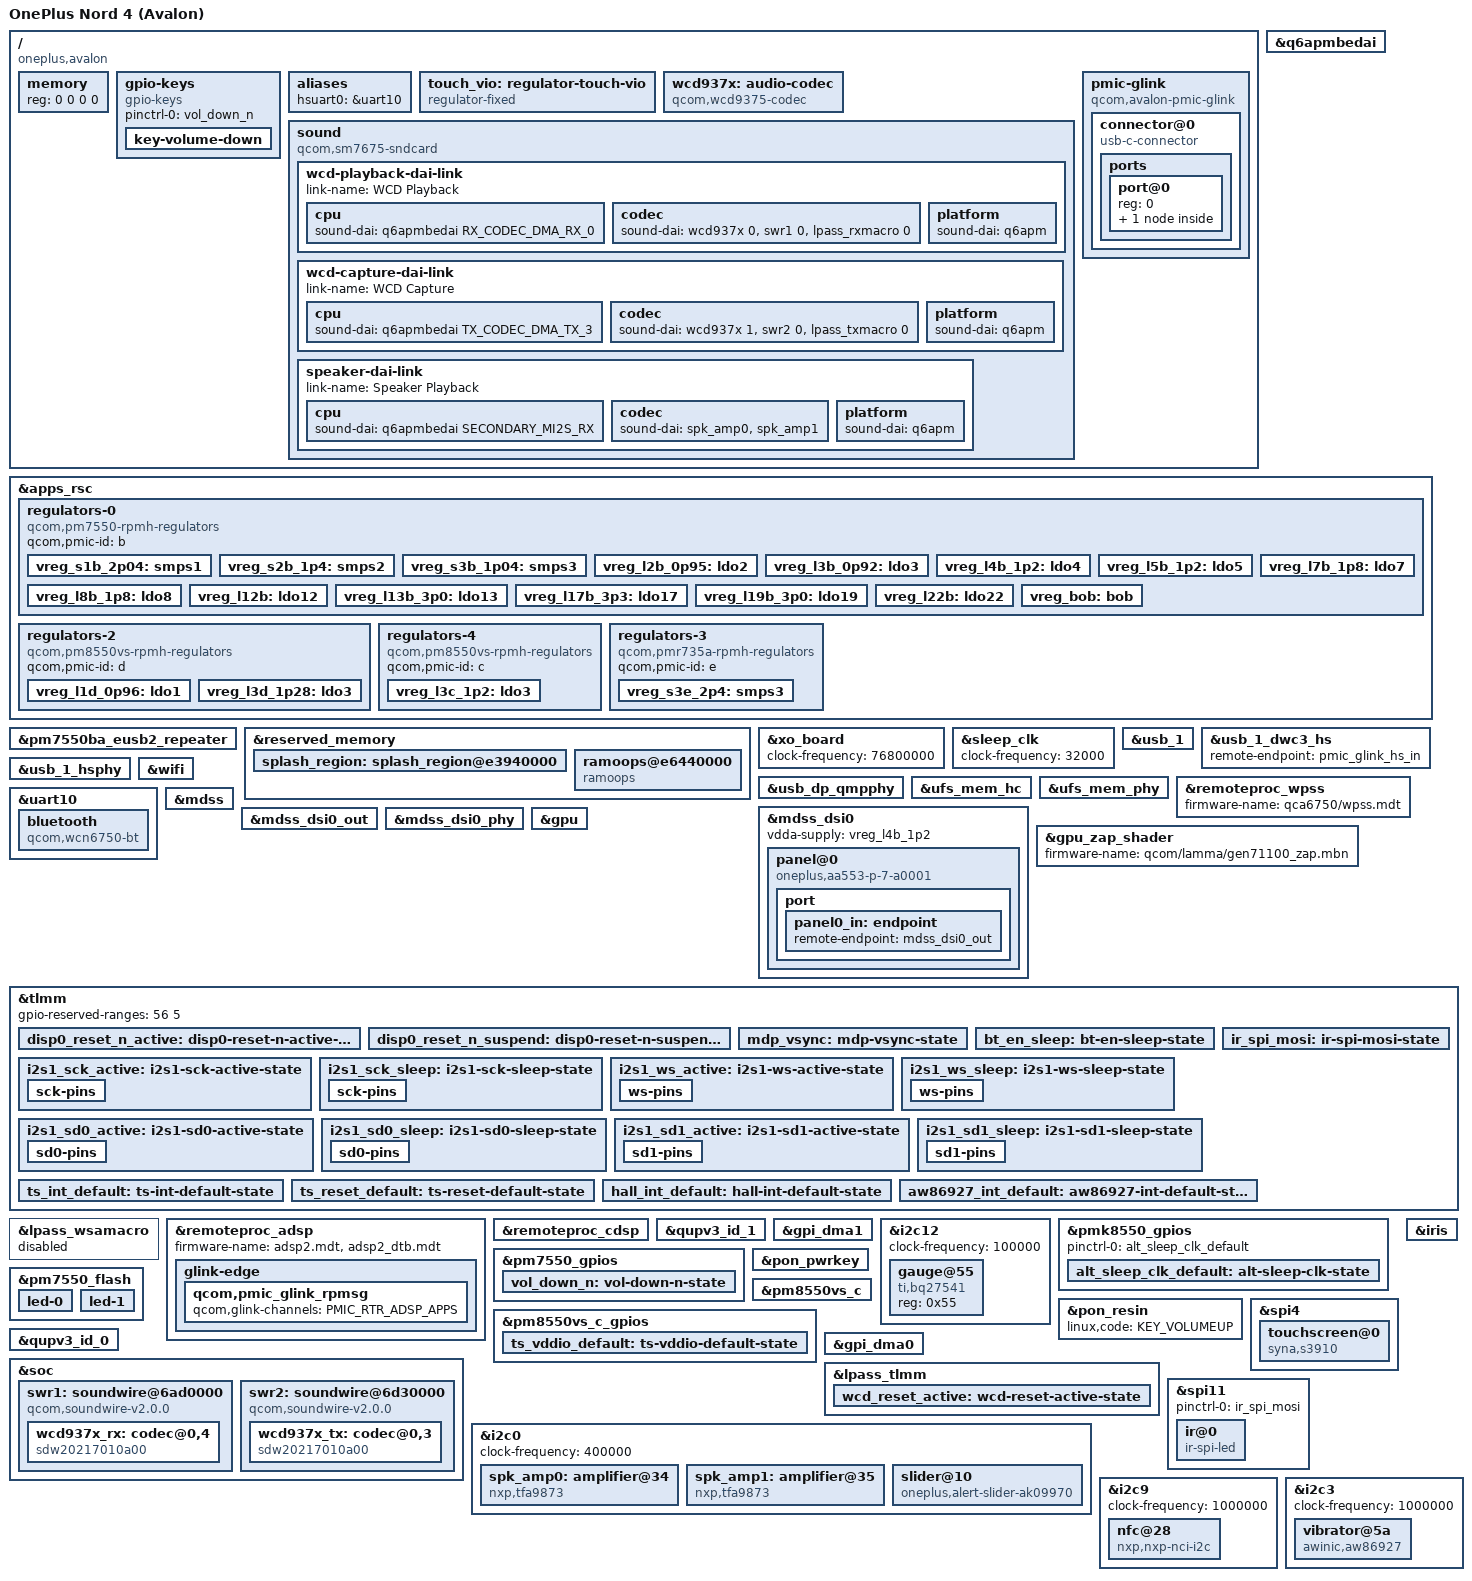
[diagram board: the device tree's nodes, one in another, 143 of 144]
// SPDX-License-Identifier: BSD-3-Clause
/*
 * OnePlus Nord 4 (Avalon), SM7675 / Lamma.
 *
 * Scope: the display subsystem and its AA553-P-7-A0001 panel, the iris video
 * decoder, the SN220U NFC controller, the AW86927 haptics motor, ramoops, the
 * USB controller with its Type-C role switch (device by default), the
 * ADSP/PMIC GLINK battery path, the WCN6750 Wi-Fi and Bluetooth path over the
 * WPSS remoteproc, the Adreno 732 GPU, the audio card and the power and
 * volume keys. SD stays disabled. The battery readout, the Wi-Fi interface,
 * the GPU probe, the panel, touch, the haptics motor, a decode and the NFC
 * controller's own answering have been exercised on hardware; the
 * charge-ceiling write, a Wi-Fi scan and the USB host role have not.
 *
 * Electrical values are from the downstream OnePlus device tree
 * (android_kernel_modules_and_devicetree_oneplus_sm7675, branch
 * oneplus/sm7675_b_16.0.0_nord_4, commit 150f7f8f3354dc680da90e83788bd25d9b983739),
 * not from the QRD reference board.
 */

/dts-v1/;

#include <dt-bindings/gpio/gpio.h>
#include <dt-bindings/input/linux-event-codes.h>
#include <dt-bindings/interrupt-controller/irq.h>
#include <dt-bindings/leds/common.h>
#include <dt-bindings/regulator/qcom,rpmh-regulator.h>
#include <dt-bindings/sound/qcom,q6dsp-lpass-ports.h>
#include "lamma.dtsi"
#include "pm7550.dtsi" /* PMXR2230 */
#include "pm7550ba.dtsi"
#include "pmr735a.dtsi"
#include "pmk8550.dtsi"
#include "pm8550vs.dtsi"

/ {
	model = "OnePlus Nord 4 (Avalon)";
	compatible = "oneplus,avalon", "qcom,lamma";
	chassis-type = "handset";

	/*
	 * Bootloader selection properties, copied from the shipped Avalon
	 * dtbo entry: qcom,msm-id 632 (0x278) for Lamma/Cliffs 7, board-id 8,
	 * and the pmic-id of eight 32-bit cells ending in 0x4c. ABL reads
	 * pmic-id-size as the number of u32 cells per entry and skips the
	 * PMIC match when the property length is not a multiple of it.
	 */
	qcom,msm-id = <0x278 0x10000>;
	qcom,board-id = <0x08 0x00>;
	qcom,pmic-id-size = <8>;
	qcom,pmic-id = <0x00 0x00 0x00 0x00 0x00 0x00 0x00 0x4c>;

	/*
	 * Lamma dtsi ships a placeholder memory@a0000000; this bootloader
	 * looks up the node named exactly "memory" and rewrites its reg with
	 * the DDR map, so the placeholder is dropped rather than left dead.
	 */
	/delete-node/ memory@a0000000;

	/* The bootloader rewrites reg with the real DDR size. */
	memory {
		device_type = "memory";
		reg = <0 0 0 0>;
	};

	/*
	 * The volume-down key is a board line: PMXR2230 GPIO6, driven low when
	 * pressed, with a 32 ms debounce. The downstream OnePlus board file
	 * deletes the reference board's key node and restates it this way
	 * (vendor/qcom/proprietary/devicetree/oplus/tp/avalon-oplus-tp-24211.dtsi:476-493),
	 * which also swaps the key code the reference board uses for this pin
	 * (KEY_VOLUMEUP in qcom/cliffs-mtp.dtsi:72-86) for KEY_VOLUMEDOWN.
	 * Volume-up and power are PMK8550 PON inputs instead; see below.
	 */
	gpio-keys {
		compatible = "gpio-keys";

		pinctrl-0 = <&vol_down_n>;
		pinctrl-names = "default";

		key-volume-down {
			label = "Volume Down";
			gpios = <&pm7550_gpios 6 GPIO_ACTIVE_LOW>;
			linux,code = <KEY_VOLUMEDOWN>;
			debounce-interval = <32>;
			linux,can-disable;
			wakeup-source;
		};
	};

	aliases {
		/*
		 * The Bluetooth UART, uart10, is neither the console nor a
		 * serial port, so it gets no "serial" alias. qcom_geni_serial
		 * asks for "serial" first and falls back to "hsuart" when the
		 * node has none (drivers/tty/serial/qcom_geni_serial.c:1821-1823);
		 * without either the probe is rejected before the port exists
		 * ("Invalid line -19"), so no tty and no serdev either.
		 * Downstream aliases the same instance the same way:
		 * hsuart0 = &qupv3_se10_4uart (cliffs.dtsi:48-53).
		 */
		hsuart0 = &uart10;
	};

	/*
	 * The S3910's 1.8 V I/O rail. The downstream Avalon node has no
	 * vcc_1v8-supply; instead it names synaptics,avdd-gpio =
	 * <&pm8550vs_c_gpios 3 0x1>, pinctrl state ts_vddio_active_primary
	 * (power-source 1 = 1.8 V), and the SPI platform driver drives that
	 * pad to synaptics,power-on-state = 1 before it enables the analog
	 * rail (android_kernel_modules_and_devicetree_oneplus_sm7675,
	 * oneplus/sm7675_b_16.0.0_nord_4, 150f7f8f3354,
	 * vendor/oplus/kernel/touchpanel/synaptics_hbp/syna_tcm2_platform_spi.c:
	 * 366-402,464-490). Model it as the switched rail it is.
	 */
	touch_vio: regulator-touch-vio {
		compatible = "regulator-fixed";
		regulator-name = "touch_vio";
		regulator-min-microvolt = <1800000>;
		regulator-max-microvolt = <1800000>;
		enable-active-high;
		gpios = <&pm8550vs_c_gpios 3 GPIO_ACTIVE_HIGH>;
	};

	/*
	 * The WCD937x codec, split into the RX and TX SoundWire slaves below.
	 * Supplies: L7B at 1.8 V feeds vdd-rxtx, vdd-px and vdd-buck (13890,
	 * 13890 and 361110 uA; rxtx and vddpx static, buck on demand) and BOB
	 * at 3.296 V feeds vdd-mic-bias at 6760 uA
	 * (audio-devicetree/cliffs-audio-overlay.dtsi:318-332 and
	 * oplus/cliffs-audio-overlay-common.dtsi:33-39). Downstream's final
	 * Avalon overlay leaves the three mic biases at 1800 mV
	 * (oplus/avalon-24211-audio-cliffs-overlay.dtsi:44-54 sets the MBHC
	 * thresholds, not the bias voltages; the bias values in
	 * cliffs-audio-overlay.dtsi:330-332 are 1800 mV). The reset line is
	 * LPASS LPI GPIO12 (see the state below).
	 *
	 * The variant is not recorded anywhere downstream: the driver accepts
	 * both ids, reads the chip id from the efuse and only prints the
	 * unknown case (sound/soc/codecs/wcd937x.c:2512-2522, :2981-2984), so
	 * the compatible pair names what the board may carry and the first
	 * boot reports which one is fitted.
	 */
	wcd937x: audio-codec {
		compatible = "qcom,wcd9375-codec", "qcom,wcd9370-codec";

		pinctrl-0 = <&wcd_reset_active>;
		pinctrl-names = "default";

		reset-gpios = <&lpass_tlmm 12 GPIO_ACTIVE_LOW>;

		vdd-buck-supply = <&vreg_l7b_1p8>;
		vdd-rxtx-supply = <&vreg_l7b_1p8>;
		vdd-px-supply = <&vreg_l7b_1p8>;
		vdd-mic-bias-supply = <&vreg_bob>;

		qcom,micbias1-microvolt = <1800000>;
		qcom,micbias2-microvolt = <1800000>;
		qcom,micbias3-microvolt = <1800000>;
		/*
		 * The board wires three mic biases (downstream enables
		 * MIC BIAS1-3 only, oplus/avalon-24211-audio-cliffs-overlay.dtsi:48-54).
		 * The binding requires the fourth value and the driver's
		 * max_bias is 3, so it never programs this one; 1.8 V is the
		 * driver's own default for an unset bias
		 * (sound/soc/codecs/wcd-common.c:36-61).
		 */
		qcom,micbias4-microvolt = <1800000>;

		qcom,rx-device = <&wcd937x_rx>;
		qcom,tx-device = <&wcd937x_tx>;

		#sound-dai-cells = <1>;
	};

	/*
	 * The one card this board can register: the AudioReach machine driver
	 * (sound/soc/qcom/sc8280xp.c, compatible added for sm7675) builds the
	 * links from this node through qcom_snd_parse_of()
	 * (sound/soc/qcom/common.c:26-172). The MI2S1 pins carry the speaker
	 * amplifiers (oplus,speaker-i2s-id = <1>,
	 * oplus/avalon-24211-audio-cliffs-overlay.dtsi:119-120) and the four
	 * active states are the ones described above; the card applies them
	 * because the q6apm DAI does not.
	 */
	sound {
		compatible = "qcom,sm7675-sndcard", "qcom,sm8450-sndcard";
		model = "OnePlus Nord 4";

		pinctrl-0 = <&i2s1_sck_active>, <&i2s1_ws_active>,
			    <&i2s1_sd0_active>, <&i2s1_sd1_active>;
		pinctrl-names = "default";

		/*
		 * The board's microphones are the WCD9370's analog ones: the
		 * bottom and top mics land on AMIC1/AMIC2 through MIC BIAS1/2
		 * (the vendor's capture backend is CODEC_DMA-LPAIF_RXTX-TX-3
		 * for both, odm/etc/resourcemanager.xml in the stock odm image),
		 * and the stock routing joins the codec's third input to MIC
		 * BIAS3 as well.  The last two routes join the codec's ADC
		 * outputs to the TX macro's SoundWire inputs: the codec's TX
		 * port mapping puts ADC1 and ADC2 on master port 2
		 * (qcom,tx-port-mapping = <2 2 3 4>, the same table the SM8550
		 * WCD9385 boards use), and master port 2 carries TX SWR_INPUT0..3
		 * (lpass-tx-macro.c's v9_2 widget set, which the SM8550 macro
		 * data selects).
		 */
		audio-routing = "AMIC1", "MIC BIAS1",
				"AMIC2", "MIC BIAS2",
				"AMIC3", "MIC BIAS3",
				"TX SWR_INPUT0", "ADC1_OUTPUT",
				"TX SWR_INPUT1", "ADC2_OUTPUT";

		wcd-playback-dai-link {
			link-name = "WCD Playback";

			cpu {
				sound-dai = <&q6apmbedai RX_CODEC_DMA_RX_0>;
			};

			codec {
				sound-dai = <&wcd937x 0>, <&swr1 0>,
					    <&lpass_rxmacro 0>;
			};

			platform {
				sound-dai = <&q6apm>;
			};
		};

		/*
		 * Capture: the WCD9370's ADCs leave the codec on the TX
		 * SoundWire slave (swr2, the TX macro's master) and reach the
		 * LPASS through the RXTX codec DMA's TX3 port.  The same link
		 * shape as qcm6490-idp.dts's wcd-capture-dai-link, whose codec
		 * is this one; the codec's first DAI is the RX, the second the
		 * TX (wcd937x.c's wcd937x_dais[]).
		 */
		wcd-capture-dai-link {
			link-name = "WCD Capture";

			cpu {
				sound-dai = <&q6apmbedai TX_CODEC_DMA_TX_3>;
			};

			codec {
				sound-dai = <&wcd937x 1>, <&swr2 0>,
					    <&lpass_txmacro 0>;
			};

			platform {
				sound-dai = <&q6apm>;
			};
		};

		/*
		 * Both amplifiers are fed from the same MI2S: downstream's
		 * oplus,speaker-i2s-id = <1> is the secondary MI2S, whose
		 * SCK/WS/SD0/SD1 are the TLMM i2s1 states above
		 * (oplus/avalon-24211-audio-cliffs-overlay.dtsi:113-148).
		 */
		speaker-dai-link {
			link-name = "Speaker Playback";

			cpu {
				sound-dai = <&q6apmbedai SECONDARY_MI2S_RX>;
			};

			codec {
				sound-dai = <&spk_amp0>, <&spk_amp1>;
			};

			platform {
				sound-dai = <&q6apm>;
			};
		};
	};
};

/*
 * The secondary MI2S bit clock is owned by the LPASS PRM, not by the DSP's
 * I2S endpoint: the DAI votes its frequency through q6prm at hw_params, as
 * the vendor's machine driver does (audio-kernel asoc/msm_common.c, the
 * CLOCK_ID_SEC_MI2S_IBIT branch of msm_common_snd_hw_params()).  Without the
 * vote the endpoint has no bit clock, so it never returns a buffer and the
 * playback hw_ptr stays 0.
 */
&q6apmbedai {
	clocks = <&q6prmcc LPASS_CLK_ID_SEC_MI2S_IBIT LPASS_CLK_ATTRIBUTE_COUPLE_NO>;
	clock-names = "sec-mi2s-ibit";
};

&apps_rsc {
	regulators-0 {
		compatible = "qcom,pm7550-rpmh-regulators";
		qcom,pmic-id = "b";

		/*
		 * S1B: WCN6750 WLAN vdd-1.8-xo and BT vddrfa1p7. 1856000-2040000 uV,
		 * init 1856000 (downstream qcom/cliffs-regulators.dtsi:344-346; the
		 * consumers are qca6750/vdd-1.8-xo at cliffs-qca6750.dtsi:84 and
		 * bt-vdd-rfa1 at cliffs-qca6750-bt.dtsi:35). Neither the ath11k nor
		 * the hci_qca probe runs before the WPSS firmware, so the rail is held
		 * on at the downstream boot voltage.
		 */
		vreg_s1b_2p04: smps1 {
			regulator-name = "vreg_s1b_2p04";
			regulator-min-microvolt = <1856000>;
			regulator-max-microvolt = <2040000>;
			regulator-initial-mode = <RPMH_REGULATOR_MODE_HPM>;
			regulator-always-on;
		};

		/*
		 * S2B: WLAN/BT vdd-1.3-rfa on the downstream board and the parent
		 * rail of UFS vccq. 1256000-1408000 uV, init 1256000
		 * (downstream qcom/cliffs-regulators.dtsi:358-364). Mainline has no
		 * consumer for the UFS parent vote, so the rail is held on.
		 */
		vreg_s2b_1p4: smps2 {
			regulator-name = "vreg_s2b_1p4";
			regulator-min-microvolt = <1256000>;
			regulator-max-microvolt = <1408000>;
			regulator-initial-mode = <RPMH_REGULATOR_MODE_HPM>;
			regulator-always-on;
		};

		/*
		 * S3B: WCN6750 WLAN vdd-cx-mx and BT vddaon, vddbtcxmx,
		 * vddrfacmn and vddrfa0p8. 968000-1040000 uV, init 984000
		 * (downstream qcom/cliffs-regulators.dtsi:377-379; the consumers are
		 * cliffs-qca6750.dtsi:82 and cliffs-qca6750-bt.dtsi:31-34). Held on
		 * for the same reason as S1B.
		 */
		vreg_s3b_1p04: smps3 {
			regulator-name = "vreg_s3b_1p04";
			regulator-min-microvolt = <968000>;
			regulator-max-microvolt = <1040000>;
			regulator-initial-mode = <RPMH_REGULATOR_MODE_HPM>;
			regulator-always-on;
		};

		/* L2B: USB HS PHY vdd. 880000-950000 uV, init 880000. */
		vreg_l2b_0p95: ldo2 {
			regulator-name = "vreg_l2b_0p95";
			regulator-min-microvolt = <880000>;
			regulator-max-microvolt = <950000>;
			regulator-initial-mode = <RPMH_REGULATOR_MODE_HPM>;
		};

		/* L3B: USB3-DP PHY vdda-pll. 880000-920000 uV. */
		vreg_l3b_0p92: ldo3 {
			regulator-name = "vreg_l3b_0p92";
			regulator-min-microvolt = <880000>;
			regulator-max-microvolt = <920000>;
			regulator-initial-mode = <RPMH_REGULATOR_MODE_HPM>;
		};

		/* L4B: USB HS PHY vdda12 and USB3-DP PHY vdda-phy. 1.2 V. */
		vreg_l4b_1p2: ldo4 {
			regulator-name = "vreg_l4b_1p2";
			regulator-min-microvolt = <1200000>;
			regulator-max-microvolt = <1200000>;
			regulator-initial-mode = <RPMH_REGULATOR_MODE_HPM>;
		};

		/*
		 * L5B: UFS vddp-ref-clk. 1.2 V, init 1200000 (downstream
		 * qcom/cliffs-regulators.dtsi:479-487). Mainline has no consumer, so
		 * the rail is held on for the UFS reset pull-up.
		 */
		vreg_l5b_1p2: ldo5 {
			regulator-name = "vreg_l5b_1p2";
			regulator-min-microvolt = <1200000>;
			regulator-max-microvolt = <1200000>;
			regulator-initial-mode = <RPMH_REGULATOR_MODE_HPM>;
			regulator-always-on;
		};

		/* L7B: eUSB2 repeater vdd18. 1.8 V. */
		vreg_l7b_1p8: ldo7 {
			regulator-name = "vreg_l7b_1p8";
			regulator-min-microvolt = <1800000>;
			regulator-max-microvolt = <1800000>;
			regulator-initial-mode = <RPMH_REGULATOR_MODE_HPM>;
		};

		/*
		 * L8B: panel vddio. 1.8 V, 220 mA proxy consumer
		 * (downstream qcom/cliffs-regulators.dtsi:520-530); the panel's
		 * supply entry asks for the same 1.8 V, enabled 2 ms before vci
		 * (vendor/qcom/proprietary/display-devicetree/oplus/
		 * audi-23803-display-cliffs-overlay.dtsi:21-29).
		 */
		vreg_l8b_1p8: ldo8 {
			regulator-name = "vreg_l8b_1p8";
			regulator-min-microvolt = <1800000>;
			regulator-max-microvolt = <1800000>;
			regulator-initial-mode = <RPMH_REGULATOR_MODE_HPM>;
		};

		/*
		 * L12B: UFS vcc. The PON sets 2.4 V or 2.96 V by UFS mode, so the
		 * downstream node has no min/max (qcom/cliffs-regulators.dtsi:602-616).
		 */
		vreg_l12b: ldo12 {
			regulator-name = "vreg_l12b";
			regulator-initial-mode = <RPMH_REGULATOR_MODE_HPM>;
		};

		/*
		 * L13B: the IR blaster's LED rail, 3.008 V. The downstream
		 * consumer_ir_core node names L13B at 3008000 uV
		 * (oplus/sensor/avalon-sensor-24211.dtsi:55-62), and the
		 * overlay removes the SD card's reference to the same rail
		 * (oplus/cliffs_overlay_common.dtsi:91-97). ir-spi-led looks
		 * its supply up as "irda_regulator" while its binding declares
		 * power-supply, so the rail is held on here rather than
		 * switched per transmission.
		 */
		vreg_l13b_3p0: ldo13 {
			regulator-name = "vreg_l13b_3p0";
			regulator-min-microvolt = <3008000>;
			regulator-max-microvolt = <3008000>;
			regulator-initial-mode = <RPMH_REGULATOR_MODE_HPM>;
			regulator-always-on;
		};

		/* L17B: eUSB2 repeater vdd3. 2700000-3300000 uV, init 3104000. */
		vreg_l17b_3p3: ldo17 {
			regulator-name = "vreg_l17b_3p3";
			regulator-min-microvolt = <2700000>;
			regulator-max-microvolt = <3300000>;
			regulator-initial-mode = <RPMH_REGULATOR_MODE_HPM>;
		};

		/*
		 * L19B: panel vci. The rail runs 2.6-3.544 V
		 * (downstream qcom/cliffs-regulators.dtsi:727-737) and the panel's
		 * supply entry fixes it at 3.0 V, enabled 15 ms before the reset
		 * sequence (vendor/qcom/proprietary/display-devicetree/oplus/
		 * audi-23803-display-cliffs-overlay.dtsi:32-43).
		 */
		vreg_l19b_3p0: ldo19 {
			regulator-name = "vreg_l19b_3p0";
			regulator-min-microvolt = <3000000>;
			regulator-max-microvolt = <3000000>;
			regulator-initial-mode = <RPMH_REGULATOR_MODE_HPM>;
		};

		/*
		 * L22B: touch vdd. 2700000-3400000 uV, init 2700000 (downstream
		 * qcom/cliffs-regulators.dtsi:781-798). The touch controller's
		 * driver raises it to 3.1 V itself.
		 */
		vreg_l22b: ldo22 {
			regulator-name = "vreg_l22b";
			regulator-min-microvolt = <2700000>;
			regulator-max-microvolt = <3400000>;
			regulator-initial-mode = <RPMH_REGULATOR_MODE_HPM>;
		};

		/*
		 * BOB: the WCD937x codec's mic-bias supply. The PMXR2230 (PM7550)
		 * BOB is the RPMh bobb1 resource: 3.008-3.96 V, init 3.296 V,
		 * and the codec draws 6760 uA from it
		 * (downstream qcom/cliffs-regulators.dtsi:821-831 and
		 * audio-devicetree/cliffs-audio-overlay.dtsi:327-332). The
		 * codec driver enables it with its other supplies at probe and
		 * never changes the voltage (sound/soc/codecs/wcd937x.c:112,
		 * :2929-2932), so the boot/PON value downstream programs is
		 * what the rail keeps.
		 */
		vreg_bob: bob {
			regulator-name = "vreg_bob";
			regulator-min-microvolt = <3008000>;
			regulator-max-microvolt = <3960000>;
			regulator-initial-mode = <RPMH_REGULATOR_MODE_HPM>;
		};
	};

	/*
	 * PM8550VS instance d holds the two UFS rails that are not on the "b"
	 * PMIC. The SPMI node itself stays disabled as in the shipped Avalon
	 * dtbo entry 1 (and in downstream qcom/cliffs-pmic-overlay.dtsi:26);
	 * these are RPMh resources, and their voltages are the downstream
	 * qcom/cliffs-regulators.dtsi values.
	 */
	regulators-2 {
		compatible = "qcom,pm8550vs-rpmh-regulators";
		qcom,pmic-id = "d";

		/* L1D: UFS PHY vdda-phy. 866000-958000 uV, init 912000. */
		vreg_l1d_0p96: ldo1 {
			regulator-name = "vreg_l1d_0p96";
			regulator-min-microvolt = <866000>;
			regulator-max-microvolt = <958000>;
			regulator-initial-mode = <RPMH_REGULATOR_MODE_HPM>;
		};

		/* L3D: UFS vccq and vccq-shutdown. 1140000-1260000 uV, init 1200000. */
		vreg_l3d_1p28: ldo3 {
			regulator-name = "vreg_l3d_1p28";
			regulator-min-microvolt = <1140000>;
			regulator-max-microvolt = <1260000>;
			regulator-initial-mode = <RPMH_REGULATOR_MODE_HPM>;
		};
	};

	/*
	 * PM8550VS instance c: the display's own 1.2 V rail. The downstream
	 * node runs 1200000-1250000 uV, initialises at 1.2 V and holds itself
	 * on with a 200 mA proxy consumer (qcom/cliffs-regulators.dtsi:855-879),
	 * so downstream has it up from boot whether the display is on or not;
	 * the display tree names it as its vdd-supply
	 * (display/cliffs-sde-display.dtsi:74). Mainline's msm driver has no
	 * such supply to bind it to, so it is kept on the way downstream keeps
	 * it.
	 */
	regulators-4 {
		compatible = "qcom,pm8550vs-rpmh-regulators";
		qcom,pmic-id = "c";

		vreg_l3c_1p2: ldo3 {
			regulator-name = "vreg_l3c_1p2";
			regulator-min-microvolt = <1200000>;
			regulator-max-microvolt = <1250000>;
			regulator-initial-mode = <RPMH_REGULATOR_MODE_HPM>;
			regulator-always-on;
		};
	};

	/*
	 * The PMR735A (instance e) carries the only rail the WCN6750 Bluetooth
	 * path needs from it: S3E, the chip's 2.2 V PA supply. This is the one
	 * PMR735A resource the board describes so far; the rest of that PMIC
	 * belongs to the display, camera and codec paths, which stay disabled.
	 */
	regulators-3 {
		compatible = "qcom,pmr735a-rpmh-regulators";
		qcom,pmic-id = "e";

		/*
		 * S3E: BT bt-vdd-ipa-2p2. 1600000-2400000 uV, init 1600000
		 * (downstream qcom/cliffs-regulators.dtsi:326-332; the consumer is
		 * bt-vdd-ipa-2p2 at cliffs-qca6750-bt.dtsi:37). hci_qca enables it
		 * with the other BT rails when the serdev probes, so it needs no
		 * regulator-always-on.
		 */
		vreg_s3e_2p4: smps3 {
			regulator-name = "vreg_s3e_2p4";
			regulator-min-microvolt = <1600000>;
			regulator-max-microvolt = <2400000>;
			regulator-initial-mode = <RPMH_REGULATOR_MODE_HPM>;
		};
	};
};

&pm7550ba_eusb2_repeater {
	vdd3-supply = <&vreg_l17b_3p3>;
	vdd18-supply = <&vreg_l7b_1p8>;
};

&reserved_memory {
	/*
	 * The bootloader splash carveout, same base and size as the shipped
	 * Avalon dtbo. The downstream display node is named splash_region;
	 * ABL powers the display down if it is not.
	 */
	splash_region: splash_region@e3940000 {
		reg = <0 0xe3940000 0 0x2b00000>;
		no-map;
	};

	/*
	 * First free range above the splash carveout: [0xe1d40000, 0xf3800000)
	 * is reserved by neither the stock 1001 base DTB nor the Avalon dtbo.
	 * Size and buffer split are the downstream ramoops_region values.
	 */
	ramoops@e6440000 {
		compatible = "ramoops";
		reg = <0 0xe6440000 0 0x240000>;
		console-size = <0x40000>;
		pmsg-size = <0x200000>;
		mem-type = <2>;
	};
};

/*
 * The board's fixed clocks are declared without a rate in lamma.dtsi/palawan.dtsi,
 * as on every Qualcomm SoC dtsi, and of_fixed_clk_setup() refuses a node without
 * clock-frequency (drivers/clk/clk-fixed-rate.c:168), so without these the XO tree
 * has no provider at all: RPMH_CXO_CLK and everything below it read 0 Hz, and the
 * eUSB2 PHY rejects its "ref" clock (F0024). 76.8 MHz CXO and 32 kHz sleep clock
 * are the downstream OnePlus cliffs values
 * (android_kernel_modules_and_devicetree_oneplus_sm7675, branch
 * oneplus/sm7675_b_16.0.0_nord_4, commit 150f7f8f3354dc680da90e83788bd25d9b983739,
 * kernel_platform/qcom/proprietary/devicetree/qcom/cliffs.dtsi:1144-1155).
 */
&xo_board {
	clock-frequency = <76800000>;
};

&sleep_clk {
	clock-frequency = <32000>;
};

/*
 * The port is dual-role. The ADSP's UCSI implementation, reached over the same
 * PMIC GLINK service as the battery manager, reports what is attached and
 * drives the controller's role switch; the controller keeps the role it has
 * today (device) unless a device such as a keyboard or a storage bridge is
 * attached, so the gadget link that is this board's console stays the
 * default.
 *
 * Downstream describes the same port both ways: a dual-role controller with
 * a role switch (kernel_platform/qcom/proprietary/devicetree/qcom/
 * cliffs-usb.dtsi:54,84 in the OnePlus SM7675 tree) wired to the PMIC GLINK
 * UCSI connector (cliffs-pm7550ba.dtsi:298-318). Mainline's UCSI client finds
 * the role switch through that connector's graph
 * (drivers/usb/typec/ucsi/ucsi.c:1697-1698) and dwc3 maps it onto the
 * controller's mode (drivers/usb/dwc3/drd.c:504-523).
 */
&usb_1 {
	dr_mode = "otg";
	usb-role-switch;
	role-switch-default-mode = "peripheral";
	maximum-speed = "high-speed";

	status = "okay";
};

/*
 * The connector's USB-2 pair. This endpoint is the graph link the UCSI client
 * follows from the connector to the role switch above. The SuperSpeed and SBU
 * lanes are not described: the port runs at high speed and DisplayPort alt
 * mode is not enabled on this board.
 */
&usb_1_dwc3_hs {
	remote-endpoint = <&pmic_glink_hs_in>;
};

&usb_1_hsphy {
	vdd-supply = <&vreg_l2b_0p95>;
	vdda12-supply = <&vreg_l4b_1p2>;

	phys = <&pm7550ba_eusb2_repeater>;

	status = "okay";
};

&usb_dp_qmpphy {
	vdda-phy-supply = <&vreg_l4b_1p2>;
	vdda-pll-supply = <&vreg_l3b_0p92>;

	status = "okay";
};

/*
 * UFS. The node set and every electrical value are the downstream Cliffs MTP
 * board's (android_kernel_modules_and_devicetree_oneplus_sm7675, branch
 * oneplus/sm7675_b_16.0.0_nord_4, commit 150f7f8f3354dc680da90e83788bd25d9b983739,
 * kernel_platform/qcom/proprietary/devicetree/qcom/cliffs-mtp.dtsi:23-69).
 * The rails are defined above: L1D/L3D on the PM8550VS d regulators-2 block,
 * L12B/S2B/L5B in regulators-0.
 *
 * Mainline's ufshcd reads only vdd-hba/vcc/vccq (drivers/ufs/host/ufshcd-pltfrm.c:181-189)
 * and the QMP UFS PHY only vdda-phy/vdda-pll (drivers/phy/qualcomm/phy-qcom-qmp-ufs.c:1299-1303),
 * so the three downstream supplies the QRD omits are recorded here but not
 * voted by a driver: vdda-qref shares L2B with the USB HS PHY's vdd and stays
 * on through that consumer; vddp-ref-clk and vccq-parent have no consumer, so
 * their rails are regulator-always-on above. The downstream vdda-phy-min-microvolt
 * of 912000 is the PON voltage and lies inside L1D's range; mainline has no
 * property for it.
 */
&ufs_mem_hc {
	vcc-supply = <&vreg_l12b>;
	vcc-max-microamp = <1200000>;

	vccq-supply = <&vreg_l3d_1p28>;
	vccq-max-microamp = <1200000>;

	qcom,vddp-ref-clk-supply = <&vreg_l5b_1p2>;
	qcom,vddp-ref-clk-max-microamp = <100>;

	qcom,vccq-parent-supply = <&vreg_s2b_1p4>;
	qcom,vccq-parent-max-microamp = <210000>;

	status = "okay";
};

&ufs_mem_phy {
	vdda-phy-supply = <&vreg_l1d_0p96>;
	vdda-pll-supply = <&vreg_l4b_1p2>;
	vdda-qref-supply = <&vreg_l2b_0p95>;

	status = "okay";
};

/*
 * WCN6750 Wi-Fi over the WPSS remoteproc. The nodes are upstream's: the
 * Palawan/Lamma dtsi already carries the WPSS PAS (palawan.dtsi:5015), the
 * WPSS and WLAN SMP2P entries (palawan.dtsi:1095-1148), the MSA carveout
 * (palawan.dtsi:931) and the Wi-Fi node (palawan.dtsi:4467). The shipped
 * Avalon dtbo names the same chip over the same link, a qcom,wcn6750 node
 * with qcom,rproc-handle = <&wpss_pas>
 * (android_kernel_modules_and_devicetree_oneplus_sm7675, branch
 * oneplus/sm7675_b_16.0.0_nord_4, commit 150f7f8f3354dc680da90e83788bd25d9b983739,
 * vendor/qcom/proprietary/wlan-devicetree/cliffs-qca6750.dtsi:34-38), and the
 * running phone carries qca_cld3_qca6750 held by icnss2 (F0007). This is the
 * WPSS path, so no PCIe controller is involved.
 *
 * The firmware name is the downstream one, qca6750/wpss.mdt
 * (kernel_platform/qcom/proprietary/devicetree/qcom/cliffs.dtsi:1660). The
 * file and its wpss.b* segments belong to the phone's own modem partition,
 * which Android mounts at /vendor/firmware_mnt; they are not part of this
 * tree and no firmware is redistributed here. ath11k additionally requests
 * ath11k/WCN6750/hw1.0/{amss.bin,m3.bin,board-2.bin}
 * (drivers/net/wireless/ath/ath11k/core.c:579-582, hw.h:74-82); the phone's
 * modem partition carries neither m3.bin nor amss.bin, so how ath11k's two
 * files map onto the vendor bundle is still open (F0035).
 */
&remoteproc_wpss {
	firmware-name = "qca6750/wpss.mdt";

	status = "okay";
};

&wifi {
	status = "okay";
};

/*
 * WCN6750 Bluetooth on the fourth QUP serial port. BT_EN is TLMM 156,
 * SW_CTRL is TLMM 80, and the supply names are the ones hci_qca looks up for
 * QCA_WCN6750 (drivers/bluetooth/hci_qca.c:2171-2184). All of it is the
 * downstream board's (vendor/qcom/proprietary/bt-devicetree/
 * cliffs-qca6750-bt.dtsi:4-45 in the OnePlus device tree pinned in F0005):
 * qcom,bt-reset-gpio on 156, qcom,bt-sw-ctrl-gpio on 80, and the bt-vdd-*
 * rails, which map to the regulators above as
 *
 *   io L7B, aon/dig/rfacmn/rfa-0p8 S3B, rfa1 (1.7 V) S1B,
 *   rfa2 (1.2 V) S2B, ipa-2p2 S3E.
 *
 * WL_EN, TLMM 35 downstream, is not described: no mainline node consumes it.
 *
 * The driver reads firmware-name as NVM then rampatch and prefixes qca/
 * (drivers/bluetooth/btqca.c:800-803, 869-874; binding
 * qcom,bluetooth-common.yaml). Only the NVM name is given: the downstream
 * node names msbtfw12.mbn as the rampatch, but that file is an ELF that
 * btqca parses as TLV, so the download always failed and only the driver's
 * ".tlv" name (msbtfw12.tlv, derived from the NVM name) can load (F0140).
 * Neither file is part of this tree and no firmware is redistributed here;
 * the server stages them under /lib/firmware/qca/ for request_firmware().
 *
 * The driver's ninth regulator, vddasd, is deprecated and not wired on this
 * board downstream, so it is left out: on a device-tree system the regulator
 * core substitutes a dummy for a missing supply
 * (drivers/regulator/core.c:130-133, 2206-2212). No max-speed is set either,
 * as downstream sets none: the qca UART protocol negotiates 3 Mbaud from its
 * own oper_speed (drivers/bluetooth/hci_qca.c:2088-2096).
 */
&uart10 {
	status = "okay";

	bluetooth {
		compatible = "qcom,wcn6750-bt";

		pinctrl-names = "default";
		pinctrl-0 = <&bt_en_sleep>;

		enable-gpios = <&tlmm 156 GPIO_ACTIVE_HIGH>;
		swctrl-gpios = <&tlmm 80 GPIO_ACTIVE_HIGH>;

		vddio-supply = <&vreg_l7b_1p8>;
		vddaon-supply = <&vreg_s3b_1p04>;
		vddbtcxmx-supply = <&vreg_s3b_1p04>;
		vddrfacmn-supply = <&vreg_s3b_1p04>;
		vddrfa0p8-supply = <&vreg_s3b_1p04>;
		vddrfa1p7-supply = <&vreg_s1b_2p04>;
		vddrfa1p2-supply = <&vreg_s2b_1p4>;
		vddrfa2p2-supply = <&vreg_s3e_2p4>;

		firmware-name = "msnv12.bin";
	};
};

/*
 * Display. The Palawan MDSS, DPU, DSI0 and DSI0 PHY nodes that palawan.dtsi
 * leaves disabled are on here, and the panel hangs off DSI0. The rails are
 * the downstream display tree's: vdda 1.2 V on L4B for the DSI controller
 * (vendor/qcom/proprietary/display-devicetree/display/cliffs-sde.dtsi:272-274),
 * and the panel's vddio and vci above. dispcc is no longer disabled: with a
 * panel driver its probe no longer stops the bootloader's splash, because
 * nothing depends on the bootloader's clock state any more.
 */
&mdss {
	status = "okay";
};

&mdss_dsi0 {
	vdda-supply = <&vreg_l4b_1p2>;

	status = "okay";

	panel@0 {
		compatible = "oneplus,aa553-p-7-a0001";
		reg = <0>;

		vddio-supply = <&vreg_l8b_1p8>;
		vci-supply = <&vreg_l19b_3p0>;

		reset-gpios = <&tlmm 79 GPIO_ACTIVE_LOW>;

		pinctrl-names = "default", "sleep";
		pinctrl-0 = <&disp0_reset_n_active>, <&mdp_vsync>;
		pinctrl-1 = <&disp0_reset_n_suspend>, <&mdp_vsync>;

		port {
			panel0_in: endpoint {
				remote-endpoint = <&mdss_dsi0_out>;
			};
		};
	};
};

&mdss_dsi0_out {
	remote-endpoint = <&panel0_in>;
	data-lanes = <0 1 2 3>;
};

&mdss_dsi0_phy {
	status = "okay";
};

/*
 * The zap shader is authenticated by the secure monitor, so it has to be the
 * file signed for this device: the build-1001 vendor partition's
 * /vendor/firmware directory lists gen71100_zap.mbn next to gen71100_sqe.fw and
 * gen71100_gmu.bin, the three names the mainline catalog asks for on chip
 * 0x43030b00 (drivers/gpu/drm/msm/adreno/a6xx_catalog.c:1618-1628). The file is
 * not added here; a later step stages the phone's copy under this path.
 */
&gpu_zap_shader {
	firmware-name = "qcom/lamma/gen71100_zap.mbn";
};

/*
 * The GPU is an Adreno 732. Downstream's cliffs7-gpu.dtsi overrides
 * qcom,gpu-model to "Adreno732" on top of cliffs-gpu.dtsi, which states the
 * gen7-11-0 compatible, chipid 0x43030b00 and the 3d00000/3d50000/3d61000/
 * 3d9e000 register windows (graphics-devicetree/gpu/cliffs-gpu.dtsi:4-19 and
 * cliffs7-gpu.dtsi:1-5). The mainline catalog maps that chip id to the a7xx
 * gen2 family and the gen71100 firmware set
 * (drivers/gpu/drm/msm/adreno/a6xx_catalog.c:1617-1628), and Lamma selects the
 * matching GMU variant (arch/arm64/boot/dts/qcom/lamma.dtsi:70-72).
 *
 * The rest of the path is already described in the SoC tree: the GPUCC with its
 * CX and GX power domains, the Adreno SMMU, the GMU node with its rscc window,
 * the gfx-mem interconnect, the OPP table and the zap-shader carveout
 * (palawan.dtsi:2354-2395, 2454-2517 and 2520-2560). The board only turns the
 * GPU node on.
 */
&gpu {
	status = "okay";
};

&tlmm {
	/*
	 * GPIOs 56-60 are owned by a trusted application and fault the XPU when
	 * the OS reads their CTL registers. gpiolib reads every GPIO's direction
	 * at gpiochip registration, so without this the TLMM probe hangs the bus
	 * (F0015). The list is the downstream OnePlus/QCOM cliffs tlmm
	 * qcom,gpios-reserved (android_kernel_modules_and_devicetree_oneplus_sm7675,
	 * branch oneplus/sm7675_b_16.0.0_nord_4, commit
	 * 150f7f8f3354dc680da90e83788bd25d9b983739,
	 * kernel_platform/qcom/proprietary/devicetree/qcom/cliffs.dtsi:741), and
	 * matches the shipped Avalon vendor_boot DTB's tlmm qcom,gpios-reserved.
	 */
	gpio-reserved-ranges = <56 5>;

	/*
	 * Panel reset and tear input. Drive strengths and biases are the
	 * downstream ones (vendor/qcom/proprietary/display-devicetree/display/
	 * cliffs-sde-display-pinctrl.dtsi:3-70); the tear pin's downstream
	 * function name mdp_vsync_p is mdp_vsync in this tree
	 * (drivers/pinctrl/qcom/pinctrl-palawan.c:797-799).
	 */
	disp0_reset_n_active: disp0-reset-n-active-state {
		pins = "gpio79";
		function = "gpio";
		drive-strength = <8>;
		bias-disable;
	};

	disp0_reset_n_suspend: disp0-reset-n-suspend-state {
		pins = "gpio79";
		function = "gpio";
		drive-strength = <2>;
		bias-pull-down;
	};

	mdp_vsync: mdp-vsync-state {
		pins = "gpio77";
		function = "mdp_vsync";
		drive-strength = <2>;
		bias-pull-down;
	};

	/*
	 * BT_EN: 2 mA, output low with a pull-down, so the chip stays off until
	 * hci_qca drives the line (downstream
	 * vendor/qcom/proprietary/bt-devicetree/cliffs-qca6750-bt.dtsi:4-16).
	 * SW_CTRL needs no state here: downstream leaves that pin at its default
	 * function.
	 */
	bt_en_sleep: bt-en-sleep-state {
		pins = "gpio156";
		function = "gpio";
		drive-strength = <2>;
		output-low;
		bias-pull-down;
	};

	/*
	 * MI2S1 carries the speaker amplifiers: the downstream audio overlay
	 * feeds both TFA98xx amps from I2S1 (oplus,speaker-i2s-id = <1>,
	 * avalon-24211-audio-cliffs-overlay.dtsi:119-120) and its pinctrl group
	 * takes the i2s1_* states (same file:65-76). The mux, sleep config and
	 * 8 mA active drive come from the downstream TLMM state definitions
	 * (qcom/cliffs-pinctrl.dtsi:1845-1856, 1874-1885, 1903-1914,
	 * 1932-1943), except the active SCK drive strength: the Avalon overlay
	 * lowers it to 4 mA (avalon-24211-audio-cliffs-overlay.dtsi:125-129).
	 * The downstream sleep config also sets input-enable; the upstream
	 * state schema rejects that property (qcom,tlmm-common.yaml:84), so the
	 * pull-down alone leaves the line an input.
	 */
	i2s1_sck_active: i2s1-sck-active-state {
		sck-pins {
			pins = "gpio123";
			function = "i2s1_sck";
			drive-strength = <4>;
			bias-disable;
		};
	};

	i2s1_sck_sleep: i2s1-sck-sleep-state {
		sck-pins {
			pins = "gpio123";
			function = "gpio";
			drive-strength = <2>;
			bias-pull-down;
		};
	};

	i2s1_ws_active: i2s1-ws-active-state {
		ws-pins {
			pins = "gpio125";
			function = "i2s1_ws";
			drive-strength = <8>;
			bias-disable;
		};
	};

	i2s1_ws_sleep: i2s1-ws-sleep-state {
		ws-pins {
			pins = "gpio125";
			function = "gpio";
			drive-strength = <2>;
			bias-pull-down;
		};
	};

	i2s1_sd0_active: i2s1-sd0-active-state {
		sd0-pins {
			pins = "gpio124";
			function = "i2s1_data0";
			drive-strength = <8>;
			bias-disable;
		};
	};

	i2s1_sd0_sleep: i2s1-sd0-sleep-state {
		sd0-pins {
			pins = "gpio124";
			function = "gpio";
			drive-strength = <2>;
			bias-pull-down;
		};
	};

	i2s1_sd1_active: i2s1-sd1-active-state {
		sd1-pins {
			pins = "gpio126";
			function = "i2s1_data1";
			drive-strength = <8>;
			bias-disable;
		};
	};

	i2s1_sd1_sleep: i2s1-sd1-sleep-state {
		sd1-pins {
			pins = "gpio126";
			function = "gpio";
			drive-strength = <2>;
			bias-pull-down;
		};
	};

	ts_int_default: ts-int-default-state {
		pins = "gpio129";
		function = "gpio";
		drive-strength = <8>;
		bias-disable;
	};

	ts_reset_default: ts-reset-default-state {
		pins = "gpio128";
		function = "gpio";
		drive-strength = <8>;
		bias-disable;
	};
};

/*
 * The board has no WSA speaker: Avalon's downstream audio overlay disables the
 * WSA macro and all four WSA amplifier nodes
 * (audio-devicetree/oplus/cliffs-audio-overlay-common.dtsi:13-35) and sets
 * qcom,wsa-max-devs = <0> (oplus/avalon-24211-audio-cliffs-overlay.dtsi:59).
 * Nothing in this tree consumes the macro's clock.
 */
&lpass_wsamacro {
	status = "disabled";
};

/*
 * Avalon downstream's cliffs-adsp_loader.dtsi names these firmware files
 * (OnePlusOSS commit 150f7f8f3354dc680da90e83788bd25d9b983739, lines 3-4).
 * A later initramfs step must source them from the phone's own
 * /vendor/firmware_mnt/image and stage them for request_firmware(); never
 * redistribute the firmware in this tree.
 */
&remoteproc_adsp {
	firmware-name = "adsp2.mdt", "adsp2_dtb.mdt";
	status = "okay";

	glink-edge {
		/*
		 * Avalon downstream cliffs.dtsi:1785-1786 exposes the PMIC
		 * charger service on this ADSP channel.
		 */
		qcom,pmic_glink_rpmsg {
			qcom,glink-channels = "PMIC_RTR_ADSP_APPS";
		};
	};
};

/*
 * The CDSP, the compute DSP behind the Hexagon HTP and the FastRPC channels.
 *
 * The SoC tree already carries the remoteproc, its GLINK edge and ten FastRPC
 * compute contexts, copied from SM8650 and disabled. Every field was checked
 * against the phone's own descriptions before this board turns the node on:
 *
 * - Downstream's node has the same base 0x32300000 and length, wdog GIC_SPI
 *   578, xo clock, cx/mxc/nsp power domains, aoss_qmp, remote-pid 5, the
 *   "stop" smem state, and the same smp2p indices under the interrupt names
 *   fatal/ready/handover/stop-ack (kernel_platform/qcom/proprietary/
 *   devicetree/qcom/cliffs.dtsi:1876-1968).
 * - The carveouts are downstream's: cdsp_mem 0x99900000 + 0x1400000 and
 *   q6_cdsp_dtb_mem 0x9ad00000 + 0x80000, with a third memory-region for the
 *   global sync region that the SM8650 PAS data assigns to the CDSP
 *   (cliffs-reserved-memory.dtsi:94-100, 150-157).
 * - The FastRPC contexts use stream IDs 0xc01-0xc08 and 0xc0c-0xc0e with
 *   stream-ID mask 0, which is what the phone's shipped Cliffs 7
 *   vendor_boot DTB carries (qcom,msm_fastrpc, label "cdsprpc-smd"); the
 *   downstream source tree has no compute-context node for this SoC, so the
 *   shipped DTB is the hardware description here.
 * - The platform data the fork maps palawan-cdsp-pas to (pas_id 18,
 *   dtb_pas_id 0x25, minidump 7, crash_reason_smem 601, ssctl 0x17, sysmon
 *   "cdsp", cdsp.mdt and cdsp_dtb.mdt) is downstream's cliffs_cdsp_resource
 *   field for field (OnePlusOSS android_kernel_oneplus_sm7675, branch
 *   oneplus/sm7675_b_16.0.0_nord_4, drivers/remoteproc/qcom_q6v5_pas.c:
 *   2541-2555; devicetree commit 150f7f8f3354dc680da90e83788bd25d9b983739).
 *
 * The firmware is not part of this tree: a test initramfs stages cdsp.mdt, its
 * .bNN segments and cdsp_dtb.mdt from the phone's own firmware_mnt image for
 * request_firmware(), and nothing here redistributes it.
 */
&remoteproc_cdsp {
	status = "okay";
};

/*
 * The sm8550-compatible PMIC GLINK client creates qcom_battmgr's battery,
 * USB and wireless power supplies. The downstream qcom,battery-charger child is
 * proprietary and has no mainline binding; do not copy it.
 *
 * The board's own compatible selects qcom_battmgr's OPPO/OnePlus variant: that
 * firmware defines battery property ids 24-26 and the 0x48 opcode differently
 * (oplus_hal_adsp.h:249-323, oplus_hal_adsp.c:3407-3410), so the driver exposes
 * the readout only and registers no charge-control setter on this board.
 */
/ {
	pmic-glink {
		compatible = "qcom,avalon-pmic-glink",
			     "qcom,sm8550-pmic-glink",
			     "qcom,pmic-glink";

		#address-cells = <1>;
		#size-cells = <0>;

		/*
		 * One connector, matching the one UCSI port the firmware
		 * reports. The graph is how the UCSI client reaches the
		 * controller's role switch above; the Type-C class and the
		 * PMIC GLINK altmode client attach to this node
		 * (Documentation/devicetree/bindings/soc/qcom/
		 * qcom,pmic-glink.yaml). Only USB-2 is described, so alt
		 * mode has no SuperSpeed or SBU mux to drive.
		 */
		connector@0 {
			compatible = "usb-c-connector";
			reg = <0>;

			power-role = "dual";
			data-role = "dual";

			ports {
				#address-cells = <1>;
				#size-cells = <0>;

				port@0 {
					reg = <0>;

					pmic_glink_hs_in: endpoint {
						remote-endpoint = <&usb_1_dwc3_hs>;
					};
				};
			};
		};
	};
};

/*
 * The pack gauge. Stock's battery power supply is the external bq27541 at I2C
 * address 0x55 on qupv3_se12_i2c at 100 kHz (oplus-chg-24211.dtsi:942-963),
 * not the ADSP's own battery object. qupv3_se12_i2c is i2c@890000 and its two
 * pins are gpio176/gpio177 on qup1_se4 (oplus-chg-24211.dtsi:788-810), which
 * palawan.dtsi's qup_i2c12_data_clk state already describes.
 *
 * bq27xxx writes a data-memory block only when the gauge has battery
 * information, and that comes from a monitored-battery node; this node has
 * none, so the gauge is read only.
 */
&qupv3_id_1 {
	status = "okay";
};

&gpi_dma1 {
	status = "okay";
};

&i2c12 {
	status = "okay";
	clock-frequency = <100000>;

	gauge@55 {
		compatible = "ti,bq27541";
		reg = <0x55>;
	};
};

/*
 * The WCN6750's PMU takes its low-frequency sleep clock from PMK8550 GPIO3,
 * which the PMIC drives in "func1" mode (the alternate sleep clock output).
 * Without it the WPSS firmware asserts as soon as the first vdev is created,
 * in its WMAC transition: "cmnos_assert.c:400:Asserted in
 * whal_wmac_recipes.c:whal_wmac_transition_to_fw_control:1734", and the
 * interface never comes up. This board's own DT carries exactly this state on
 * this pin: the stock dtbo's Avalon overlay (entry1.dtbo, pinctrl@b800) has
 * pins "gpio3", function "func1", input-disable, output-enable, bias-disable
 * and power-source 0, and the downstream board file repeats it
 * (vendor/qcom/proprietary/devicetree/qcom/cliffs-pmic-overlay.dtsi:81). The
 * same fix with a different pin is what the upstream WCN6755 bring-up needed
 * for the identical assert. The state is the GPIO controller's own default
 * state, so it is claimed when that controller registers, before the WPSS is
 * started.
 */
&pmk8550_gpios {
	pinctrl-0 = <&alt_sleep_clk_default>;
	pinctrl-names = "default";

	alt_sleep_clk_default: alt-sleep-clk-state {
		pins = "gpio3";
		function = "func1";
		input-disable;
		output-enable;
		bias-disable;
		power-source = <0>;
	};
};

/*
 * The volume-down key's pin state, as the downstream OnePlus board file
 * declares it: PMXR2230 GPIO6 in normal-function input mode, powered from
 * VIN1 (vendor/qcom/proprietary/devicetree/oplus/tp/avalon-oplus-tp-24211.dtsi:95-104).
 * That file deletes the reference board's state, which also enables the PMIC
 * pull-up (qcom/cliffs-pmic-overlay.dtsi:50-59, and the same pin in upstream
 * arch/arm64/boot/dts/qcom/sm8650-qrd.dts:1006-1013), and the key it describes
 * is ACTIVE_LOW. The pull-up is kept here: with the pull-up dropped and no
 * external one proven, the input would float when the key is open.
 */
&pm7550_gpios {
	vol_down_n: vol-down-n-state {
		pins = "gpio6";
		function = "normal";
		bias-pull-up;
		input-enable;
		power-source = <1>;
	};
};

/*
 * The power and volume-up keys are the PMK8550 PON's KPDPWR and KPDPWR_RESIN
 * inputs. The downstream tree binds both on the PON with an edge-both
 * interrupt and reports the resin as KEY_VOLUMEUP
 * (vendor/qcom/proprietary/devicetree/qcom/pmk8550.dtsi:138-149); upstream
 * ships both disabled so that a board says whether it uses them.
 */
&pon_pwrkey {
	status = "okay";
};

&pon_resin {
	linux,code = <KEY_VOLUMEUP>;

	status = "okay";
};

/*
 * The rear flash is the PMXR2230's flash-LED module, which the downstream
 * board leaves enabled (vendor/qcom/proprietary/devicetree/qcom/cliffs-mtp.dtsi:104-106)
 * and the stock camera overlays drive as two LEDs of two channels each: the
 * wide camera's flash is channels 1+2 and the ultrawide one's is 3+4
 * (vendor/qcom/proprietary/camera-devicetree/oplus/avalon_camera_overlay_common.dtsi:5-24).
 * Both of those overlays select the module's all-channel switch
 * (pmxr2230_switch2, mask 15), not the reference board's 1+4 and 2+3 pairs,
 * so the camera's pairs are the ones described here. Only the torch is
 * described — no flash-max-* properties, so the strobe path stays
 * unreachable — and each LED is limited to a tenth of the downstream torch
 * current of 500 mA per channel (qcom/pmxr2230.dtsi:167-201), which the
 * driver splits across the two channels.
 */
&pm7550_flash {
	status = "okay";

	led-0 {
		function = LED_FUNCTION_FLASH;
		color = <LED_COLOR_ID_WHITE>;
		function-enumerator = <0>;
		led-sources = <1>, <2>;
		led-max-microamp = <50000>;
	};

	led-1 {
		function = LED_FUNCTION_FLASH;
		color = <LED_COLOR_ID_WHITE>;
		function-enumerator = <1>;
		led-sources = <3>, <4>;
		led-max-microamp = <50000>;
	};
};

/*
 * The PMIC that owns the touch controller's I/O-rail switch. The downstream
 * Avalon DT enables this PM8550VS instance and its touch node names one of
 * its GPIOs (pm8550vs_c_gpios 3) as synaptics,avdd-gpio
 * (kernel_platform/qcom/proprietary/devicetree/oplus/tp/avalon-oplus-tp-24211.dtsi:1-9,266).
 */
&pm8550vs_c {
	status = "okay";
};

&pm8550vs_c_gpios {
	/*
	 * The pad that switches the S3910's 1.8 V I/O rail. The downstream
	 * ts_vddio_active_primary state selects this same power source:
	 * power-source = <1> is 1.8 V
	 * (avalon-oplus-tp-24211.dtsi:1-9). The SPI platform driver drives
	 * the pad to power-on-state = 1 when it powers the controller
	 * (syna_tcm2_platform_spi.c:366-402,464-490), so the pad is an output
	 * here and the state only selects the voltage domain.
	 */
	ts_vddio_default: ts-vddio-default-state {
		pins = "gpio3";
		function = "normal";
		power-source = <1>;
		bias-disable;
	};
};

/*
 * Touch. The S3910 sits on qupv3_se4_spi (chip select 0) at 19 MHz, with a
 * level-low interrupt on TLMM 129, an active-low reset on TLMM 128, its
 * analog rail on L22B and its 1.8 V I/O rail switched by pm8550vs_c GPIO 3;
 * the values are the downstream Avalon touch node
 * (kernel_platform/qcom/proprietary/devicetree/oplus/tp/avalon-oplus-tp-24211.dtsi:247-286).
 * It runs its own firmware and speaks TouchComm v1, so no firmware download
 * is needed from the host.
 */
&spi4 {
	status = "okay";

	touchscreen@0 {
		compatible = "syna,s3910";
		reg = <0>;

		spi-max-frequency = <19000000>;

		interrupt-parent = <&tlmm>;
		interrupts = <129 IRQ_TYPE_LEVEL_LOW>;

		reset-gpios = <&tlmm 128 GPIO_ACTIVE_LOW>;
		vdd-supply = <&vreg_l22b>;
		vio-supply = <&touch_vio>;

		pinctrl-names = "default";
		pinctrl-0 = <&ts_int_default>, <&ts_reset_default>,
			    <&ts_vddio_default>;
	};
};

/*
 * The QUP0 wrapper and its GPI DMA, which own spi4. palawan.dtsi leaves both
 * disabled and only spi4 is enabled above, so the SPI controller never probes
 * and the touch screen's node never becomes a spi_device: the first touch boot
 * showed the driver registered and no SPI device, and the second showed
 * "a90000.spi: deferred probe pending: geni_spi: Failed to get tx DMA ch".
 */
&qupv3_id_0 {
	status = "okay";
};

&gpi_dma0 {
	status = "okay";
};

/*
 * Audio. The board's codec is a WCD937x in its split form: an RX slave and a
 * TX slave on two SoundWire controllers that belong to the LPASS RX and VA
 * macros. Every register address, interrupt, clock and per-port write below is
 * from the downstream Avalon/Lamma sources
 * (android_kernel_modules_and_devicetree_oneplus_sm7675,
 * oneplus/sm7675_b_16.0.0_nord_4, 150f7f8f3354dc680da90e83788bd25d9b983739):
 * the two master nodes in vendor/qcom/proprietary/audio-devicetree/
 * cliffs-audio-overlay.dtsi:26-72 (VA master, id 3) and :138-173 (RX master,
 * id 2), and the two codec ports of the card in the same file's
 * :288-337.
 *
 * The per-port frame parameters are not in the downstream DT. The downstream
 * codec driver computes the TX master's from the codec's
 * qcom,swr-tx-port-params (oplus/avalon-24211-audio-cliffs-overlay.dtsi:307-310)
 * at stream setup, and the RX master's come from a static table in the
 * machine driver: asoc/pineapple-port-config.h:118-131
 * (rx_frame_params_default, the table the cliffs build compiles in -- the
 * board's card compatible is qcom,pineapple-asoc-snd), pushed into the master
 * through lpass_cdc_set_port_map() (asoc/pineapple.c:2249-2250) and applied by
 * swrm_get_port_config()/copy_port_tables() (soc/swr-mstr-ctrl.c:806-829,
 * :788-802). Mainline needs the same numbers as DT properties, in the order
 * "out ports followed by in ports", port i+1 at index i
 * (drivers/soundwire/qcom.c:1416-1501).
 */
&soc {
	swr1: soundwire@6ad0000 {
		compatible = "qcom,soundwire-v2.0.0";
		reg = <0 0x06ad0000 0 0x10000>;

		interrupts = <GIC_SPI 155 IRQ_TYPE_LEVEL_HIGH 0>;

		clocks = <&lpass_rxmacro>;
		clock-names = "iface";

		label = "RX";

		pinctrl-0 = <&rx_swr_active>;
		pinctrl-names = "default";

		qcom,ports-sinterval = /bits/ 16 <
			0x0003 0x003f 0x001f 0x0007 0x0000 0x018f
			0xffff 0xffff 0xffff 0xffff 0xffff 0xffff>;
		qcom,ports-offset1 = /bits/ 8 <
			0x00 0x00 0x0b 0x01 0x00 0x00
			0xff 0xff 0xff 0xff 0xff 0xff>;
		qcom,ports-offset2 = /bits/ 8 <
			0x00 0x00 0x0b 0x00 0x00 0x00
			0xff 0xff 0xff 0xff 0xff 0xff>;
		qcom,ports-block-pack-mode = /bits/ 8 <
			0xff 0x00 0x01 0xff 0x00 0x00
			0xff 0xff 0xff 0xff 0xff 0xff>;
		qcom,ports-hstart = /bits/ 8 <
			0xff 0x03 0xff 0xff 0xff 0x08
			0xff 0xff 0x00 0xff 0xff 0xff>;
		qcom,ports-hstop = /bits/ 8 <
			0xff 0x06 0xff 0xff 0xff 0x08
			0xff 0xff 0x0f 0xff 0xff 0xff>;
		qcom,ports-word-length = /bits/ 8 <
			0x01 0x07 0x04 0xff 0xff 0x0f
			0xff 0xff 0x18 0xff 0xff 0xff>;
		qcom,ports-block-group-count = /bits/ 8 <
			0xff 0xff 0xff 0xff 0x00 0x00
			0xff 0xff 0x00 0xff 0xff 0xff>;
		qcom,ports-lane-control = /bits/ 8 <
			0x01 0x00 0x00 0x00 0x00 0x00
			0xff 0xff 0x01 0xff 0xff 0xff>;

		#address-cells = <2>;
		#size-cells = <0>;
		#sound-dai-cells = <1>;
	};

	swr2: soundwire@6d30000 {
		compatible = "qcom,soundwire-v2.0.0";
		reg = <0 0x06d30000 0 0x10000>;

		interrupts = <GIC_SPI 496 IRQ_TYPE_LEVEL_HIGH 0>,
			     <GIC_SPI 520 IRQ_TYPE_LEVEL_HIGH 0>;
		interrupt-names = "core", "wakeup";

		clocks = <&lpass_txmacro>;
		clock-names = "iface";

		label = "VA";

		pinctrl-0 = <&tx_swr_active>;
		pinctrl-names = "default";

		qcom,ports-sinterval-low = /bits/ 8 <
			0xff 0xff 0xff 0xff 0xff>;
		qcom,ports-offset1 = /bits/ 8 <
			0x00 0x01 0x01 0x01 0x00>;
		qcom,ports-offset2 = /bits/ 8 <
			0x00 0x00 0x00 0x00 0x00>;
		qcom,ports-block-pack-mode = /bits/ 8 <
			0xff 0xff 0xff 0xff 0xff>;
		qcom,ports-lane-control = /bits/ 8 <
			0x00 0x00 0x00 0x00 0x00>;

		#address-cells = <2>;
		#size-cells = <0>;
		#sound-dai-cells = <1>;
	};
};

/*
 * The codec's reset pad: LPASS LPI GPIO12 as a plain GPIO, active low, 6 mA,
 * no bias, left high (reset released). Downstream describes the same pad as
 * wcd_reset_active with 16 mA and output-high
 * (audio-devicetree/cliffs-lpi.dtsi:1669-1681) and the Avalon overlay lowers
 * the drive to 6 mA (oplus/avalon-24211-audio-cliffs-overlay.dtsi:150-153).
 * The state is needed because the LPI pinctrl has no gpio_request_enable op,
 * so claiming the GPIO does not mux it
 * (drivers/pinctrl/qcom/pinctrl-lpass-lpi.c:170-175).
 */
&lpass_tlmm {
	wcd_reset_active: wcd-reset-active-state {
		pins = "gpio12";
		function = "gpio";
		drive-strength = <6>;
		bias-disable;
		output-high;
	};
};

/*
 * The codec's two SoundWire slaves. Their compatible is the SoundWire
 * enumeration id (mfg 0x0217, part 0x010a) that the mainline slave driver
 * matches (sound/soc/codecs/wcd937x-sdw.c:1066-1069). The reg cell pair is a
 * link id and the part's unique id; 4 for the RX and 3 for the TX slave are
 * the ids this part reports on hardware (Documentation/devicetree/bindings/
 * sound/qcom,wcd937x-sdw.yaml:88-104, the same pair in
 * arch/arm64/boot/dts/qcom/qcm6490-idp.dts:938-977 for a WCD9370).
 * The port mappings are the static ones downstream writes for this board:
 * RX HPH->1, CLSH->2, COMP->3, LO->4, DSD->5
 * (audio-devicetree/cliffs-audio-overlay.dtsi:292-299) and TX 1/2->2, 3->3,
 * 4->4 (the VA master's SWRM_TX1..TX3 channel groups,
 * cliffs-audio-overlay.dtsi:55-60, and the WCD9370 mapping in the binding
 * above). The channel maps are left out: downstream's mask values do not
 * translate one-for-one and capture is not part of this bring-up.
 */
&swr1 {
	wcd937x_rx: codec@0,4 {
		compatible = "sdw20217010a00";
		reg = <0 4>;

		qcom,rx-port-mapping = <1 2 3 4 5>;
		qcom,rx-channel-mapping = /bits/ 8 <1 2 1 1 2 1 2 1>;
	};
};

&swr2 {
	wcd937x_tx: codec@0,3 {
		compatible = "sdw20217010a00";
		reg = <0 3>;

		qcom,tx-port-mapping = <2 2 3 4>;

	};
};

/*
 * The speaker amplifiers: two NXP TFA9873s on the qupv3 SE0 I2C bus
 * (i2c@a80000, IRQ 353, 400 kHz), addresses 0x34 and 0x35, one per channel,
 * each with its own reset line on the main TLMM -- 127 for channel 0 and 131
 * for channel 1, both active high -- and both supplied from L7B at 1.8 V
 * (audio-devicetree/oplus/avalon-24211-audio-cliffs-overlay.dtsi:80-102, the
 * bus in cliffs-qupv3.dtsi:86-97, the supply L7B in
 * qcom/cliffs-regulators.dtsi:499-506). The vendor node carries its
 * calibration ranges (tfa_min_range 5000, tfa_max_range 8000,
 * tfa_default_mohm 8000 and 6300, tfa_channel 0 and 1); this driver has no
 * calibration path yet, so they are not repeated here.
 *
 * The downstream reset is a bare line the vendor driver drives: the pin's
 * TLMM default function is GPIO, and msm_gpio_request_enable() muxes it on
 * request, so no pinctrl state is needed.
 */
&i2c0 {
	status = "okay";
	clock-frequency = <400000>;

	spk_amp0: amplifier@34 {
		compatible = "nxp,tfa9873";
		reg = <0x34>;

		reset-gpios = <&tlmm 127 GPIO_ACTIVE_HIGH>;
		vddd-supply = <&vreg_l7b_1p8>;

		#sound-dai-cells = <0>;
	};

	spk_amp1: amplifier@35 {
		compatible = "nxp,tfa9873";
		reg = <0x35>;

		reset-gpios = <&tlmm 131 GPIO_ACTIVE_HIGH>;
		vddd-supply = <&vreg_l7b_1p8>;

		#sound-dai-cells = <0>;
	};

	/*
	 * The alert slider's hall sensor: an AKM AK09970 at 0x10 on this same
	 * SE0 bus, interrupt on GPIO 136, supplied from L11B at 1.8 V
	 * (F0284; the vendor node is oplus/tp/avalon-oplus-tp-24211.dtsi:33-55
	 * and the base DTB keeps i2c@a80000 enabled). The slider magnet moves
	 * along the sensor's Y axis; the two raw readings below separate the
	 * three detents. The input layer reports them on ABS_SND_PROFILE, the
	 * convention the OnePlus 6 GPIO slider uses.
	 */
	slider@10 {
		compatible = "oneplus,alert-slider-ak09970";
		reg = <0x10>;

		interrupt-parent = <&tlmm>;
		interrupts = <136 IRQ_TYPE_EDGE_RISING>;

		pinctrl-0 = <&hall_int_default>;
		pinctrl-names = "default";

		oneplus,axis = "x";
		oneplus,position-thresholds = <(-4700) 4000>;
		oneplus,position-map = <SND_PROFILE_RING SND_PROFILE_VIBRATE SND_PROFILE_SILENT>;
	};
};

/*
 * The IR blaster. The vendor driver is oplus_sensor_kookong_ir_spi.ko, whose
 * only output is the SPI MOSI line; the shipped DTBO puts it at chip select 0
 * of qupv3_se11_spi (dtbo_b_0.dts fragment@68, alias qupv3_se11_spi = spi@88c000,
 * spi-max-frequency 5 MHz) and muxes only GPIO 45 as qup1_se3_l1
 * (fragment@67). The LED rail is L13B at 3.008 V (oplus/sensor/
 * avalon-sensor-24211.dtsi:55-62). ir-spi-led drives the LED straight from
 * MOSI, so the CLK, MISO and CS pads stay in their board functions.
 */
&spi11 {
	status = "okay";

	pinctrl-0 = <&ir_spi_mosi>;
	pinctrl-names = "default";

	ir@0 {
		compatible = "ir-spi-led";
		reg = <0>;

		spi-max-frequency = <5000000>;
		power-supply = <&vreg_l13b_3p0>;
	};
};

/*
 * The video core. The vpu30_2v firmware is a signed blob the vendor image
 * carries at /vendor/firmware; it has to be installed as
 * /lib/firmware/qcom/vpu/vpu30_2v.mbn before the decoder can be opened.
 */
&iris {
	status = "okay";
};

/*
 * The NFC controller: NXP SN220U, PN560-class, at 0x28 on the qupv3 SE9 bus
 * (i2c@884000, IRQ 583, 1 MHz). The shipped DTBO adds it to qupv3_se9_i2c as
 * qcom,sn-nci with the interrupt on GPIO 61, enable on GPIO 114 and clock
 * request on GPIO 115 (dtbo_b_0.dts fragment@73, the same in both slots). The
 * shipped base DTB's nfc_int_active/nfc_enable_active states leave GPIO 61 an
 * input with a pull-down and GPIO 114/115 as plain GPIOs, which is the state
 * ABL hands over; the nxp,nci binding has no clock-request property, so GPIO
 * 115 is left alone. The supply is L5B at 1.2 V, held on by the UFS reset
 * pull-up comment above. docs/plans/nfc.md, F0291.
 */
&i2c9 {
	status = "okay";
	clock-frequency = <1000000>;

	nfc@28 {
		compatible = "nxp,nxp-nci-i2c";
		reg = <0x28>;

		interrupt-parent = <&tlmm>;
		interrupts = <61 IRQ_TYPE_LEVEL_HIGH>;

		enable-gpios = <&tlmm 114 GPIO_ACTIVE_HIGH>;
	};
};

/*
 * The vibration motor. The downstream board file puts an Awinic haptics IC on
 * qupv3_se3_i2c at address 0x5a, reset on TLMM 147, interrupt on TLMM 145, and
 * the node's own comment names the part aw86927
 * (android_kernel_modules_and_devicetree_oneplus_sm7675, branch
 * oneplus/sm7675_b_16.0.0_nord_4, commit 150f7f8f3354dc680da90e83788bd25d9b983739,
 * kernel_platform/qcom/proprietary/devicetree/oplus/oplus_misc/oplus-misc-24211.dtsi:36-60).
 * The same file runs that bus at 1 MHz (:37) and disables the shared PM8550B
 * haptics peripheral (:32-34), which mainline's pm7550ba.dtsi does not
 * describe (69 lines, no haptics child). qupv3_se3_i2c is i2c@a8c000
 * (palawan.dtsi:1867) with its data pins on gpio12/gpio13 in the qup0_se3
 * function (palawan.dtsi:3895-3901), which the controller's own
 * qup_i2c3_data_clk state already selects.
 *
 * The same board file also carries a second, alternative haptics node at 0x6b,
 * compatible "silicon,sih_haptic_688X", on the same two GPIOs and also
 * enabled (:62-76), so it does not say which of the two is populated. Only the
 * Awinic side has a mainline driver: drivers/input/misc/aw86927.c, binding
 * Documentation/devicetree/bindings/input/awinic,aw86927.yaml. The driver
 * resets the part, reads the chip id at 0x57/0x58 and refuses anything but
 * 0x9270 or 0x9380 (aw86927.c:737-762), so a board fitted with the other part
 * fails that check and registers no input device; the probe result is what
 * says which one this unit carries.
 */
&i2c3 {
	status = "okay";
	clock-frequency = <1000000>;

	vibrator@5a {
		compatible = "awinic,aw86927";
		reg = <0x5a>;

		interrupts-extended = <&tlmm 145 IRQ_TYPE_EDGE_FALLING>;
		reset-gpios = <&tlmm 147 GPIO_ACTIVE_LOW>;

		pinctrl-0 = <&aw86927_int_default>;
		pinctrl-names = "default";
	};
};

&tlmm {
	/* The IR blaster's MOSI pad: the only line the LED uses. */
	ir_spi_mosi: ir-spi-mosi-state {
		pins = "gpio45";
		function = "qup1_se3";
		drive-strength = <2>;
		bias-disable;
	};

	/* The hall sensor's INT output, a push-pull active-high line. */
	hall_int_default: hall-int-default-state {
		pins = "gpio136";
		function = "gpio";
		drive-strength = <2>;
		bias-disable;
	};

	/*
	 * The interrupt line as the downstream board file configures it
	 * (oplus-misc-24211.dtsi:15-30): 2 mA, input, pulled up. Its
	 * input-enable is left out because the TLMM binding rejects that
	 * property (qcom,tlmm-common.yaml:84); the line is requested as an
	 * input through the interrupt.
	 */
	aw86927_int_default: aw86927-int-default-state {
		pins = "gpio145";
		function = "gpio";
		drive-strength = <2>;
		bias-pull-up;
	};
};
